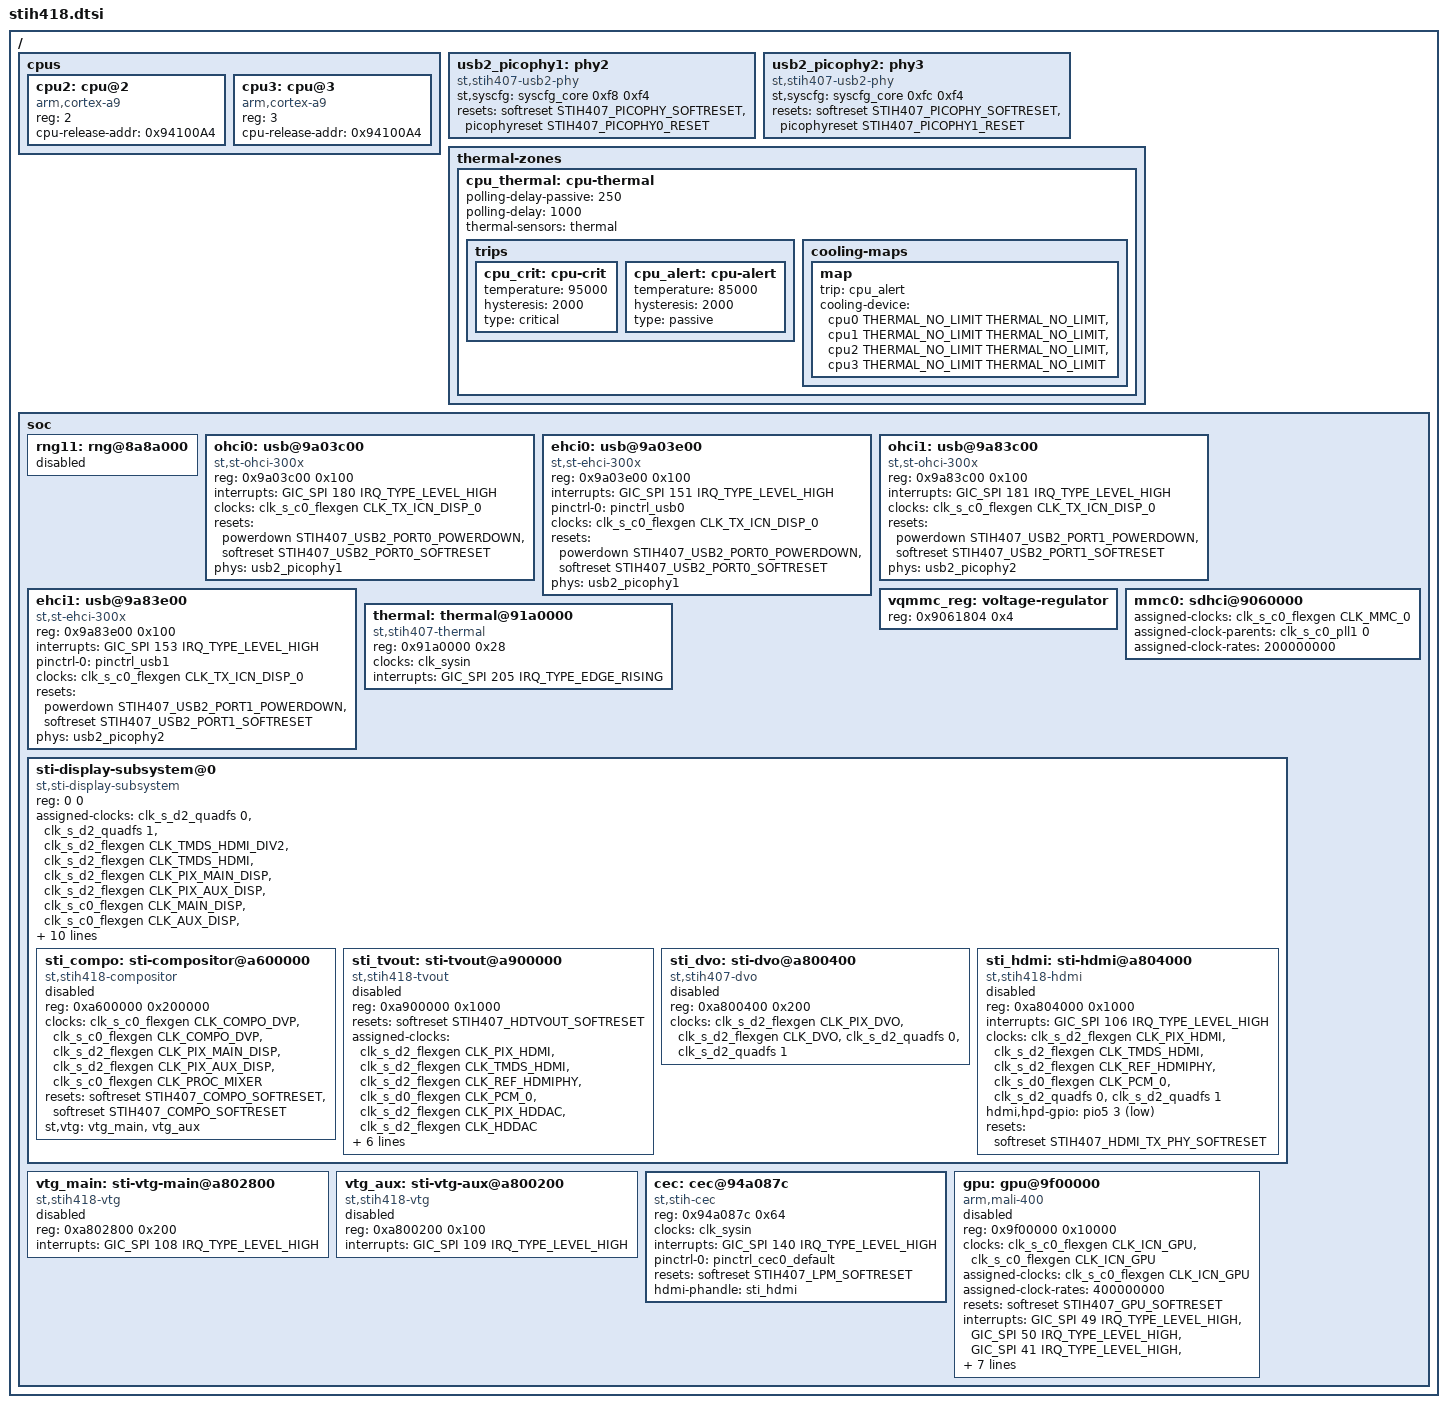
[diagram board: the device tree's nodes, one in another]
// SPDX-License-Identifier: GPL-2.0-only
/*
 * Copyright (C) 2014 STMicroelectronics Limited.
 * Author: Peter Griffin <peter.griffin@linaro.org>
 */
#include "stih418-clock.dtsi"
#include "stih407-family.dtsi"
#include "stih410-pinctrl.dtsi"
#include <dt-bindings/gpio/gpio.h>
#include <dt-bindings/thermal/thermal.h>
/ {
	cpus {
		#address-cells = <1>;
		#size-cells = <0>;
		cpu2: cpu@2 {
			device_type = "cpu";
			compatible = "arm,cortex-a9";
			reg = <2>;
			/* u-boot puts hpen in SBC dmem at 0xa4 offset */
			cpu-release-addr = <0x94100A4>;
			#cooling-cells = <2>;
		};
		cpu3: cpu@3 {
			device_type = "cpu";
			compatible = "arm,cortex-a9";
			reg = <3>;
			/* u-boot puts hpen in SBC dmem at 0xa4 offset */
			cpu-release-addr = <0x94100A4>;
			#cooling-cells = <2>;
		};
	};

	usb2_picophy1: phy2 {
		compatible = "st,stih407-usb2-phy";
		#phy-cells = <0>;
		st,syscfg = <&syscfg_core 0xf8 0xf4>;
		resets = <&softreset STIH407_PICOPHY_SOFTRESET>,
			 <&picophyreset STIH407_PICOPHY0_RESET>;
		reset-names = "global", "port";
	};

	usb2_picophy2: phy3 {
		compatible = "st,stih407-usb2-phy";
		#phy-cells = <0>;
		st,syscfg = <&syscfg_core 0xfc 0xf4>;
		resets = <&softreset STIH407_PICOPHY_SOFTRESET>,
			 <&picophyreset STIH407_PICOPHY1_RESET>;
		reset-names = "global", "port";
	};

	thermal-zones {
		cpu_thermal: cpu-thermal {
			polling-delay-passive = <250>;  /* 250ms */
			polling-delay = <1000>;         /* 1000ms */

			thermal-sensors = <&thermal>;

			trips {
				cpu_crit: cpu-crit {
					temperature = <95000>;  /* 95C */
					hysteresis = <2000>;
					type = "critical";
				};
				cpu_alert: cpu-alert {
					temperature = <85000>;  /* 85C */
					hysteresis = <2000>;
					type = "passive";
				};
			};

			cooling-maps {
				map {
					trip = <&cpu_alert>;
					cooling-device = <&cpu0 THERMAL_NO_LIMIT THERMAL_NO_LIMIT>,
							 <&cpu1 THERMAL_NO_LIMIT THERMAL_NO_LIMIT>,
							 <&cpu2 THERMAL_NO_LIMIT THERMAL_NO_LIMIT>,
							 <&cpu3 THERMAL_NO_LIMIT THERMAL_NO_LIMIT>;
				};
			};
		};
	};

	soc {
		rng11: rng@8a8a000 {
			status = "disabled";
		};

		ohci0: usb@9a03c00 {
			compatible = "st,st-ohci-300x";
			reg = <0x9a03c00 0x100>;
			interrupts = <GIC_SPI 180 IRQ_TYPE_LEVEL_HIGH>;
			clocks = <&clk_s_c0_flexgen CLK_TX_ICN_DISP_0>;
			resets = <&powerdown STIH407_USB2_PORT0_POWERDOWN>,
				 <&softreset STIH407_USB2_PORT0_SOFTRESET>;
			reset-names = "power", "softreset";
			phys = <&usb2_picophy1>;
			phy-names = "usb";
		};

		ehci0: usb@9a03e00 {
			compatible = "st,st-ehci-300x";
			reg = <0x9a03e00 0x100>;
			interrupts = <GIC_SPI 151 IRQ_TYPE_LEVEL_HIGH>;
			pinctrl-names = "default";
			pinctrl-0 = <&pinctrl_usb0>;
			clocks = <&clk_s_c0_flexgen CLK_TX_ICN_DISP_0>;
			resets = <&powerdown STIH407_USB2_PORT0_POWERDOWN>,
				 <&softreset STIH407_USB2_PORT0_SOFTRESET>;
			reset-names = "power", "softreset";
			phys = <&usb2_picophy1>;
			phy-names = "usb";
		};

		ohci1: usb@9a83c00 {
			compatible = "st,st-ohci-300x";
			reg = <0x9a83c00 0x100>;
			interrupts = <GIC_SPI 181 IRQ_TYPE_LEVEL_HIGH>;
			clocks = <&clk_s_c0_flexgen CLK_TX_ICN_DISP_0>;
			resets = <&powerdown STIH407_USB2_PORT1_POWERDOWN>,
				 <&softreset STIH407_USB2_PORT1_SOFTRESET>;
			reset-names = "power", "softreset";
			phys = <&usb2_picophy2>;
			phy-names = "usb";
		};

		ehci1: usb@9a83e00 {
			compatible = "st,st-ehci-300x";
			reg = <0x9a83e00 0x100>;
			interrupts = <GIC_SPI 153 IRQ_TYPE_LEVEL_HIGH>;
			pinctrl-names = "default";
			pinctrl-0 = <&pinctrl_usb1>;
			clocks = <&clk_s_c0_flexgen CLK_TX_ICN_DISP_0>;
			resets = <&powerdown STIH407_USB2_PORT1_POWERDOWN>,
				 <&softreset STIH407_USB2_PORT1_SOFTRESET>;
			reset-names = "power", "softreset";
			phys = <&usb2_picophy2>;
			phy-names = "usb";
		};

		vqmmc_reg: voltage-regulator {
			reg = <0x9061804 0x4>;
		};

		mmc0: sdhci@9060000 {
			assigned-clocks = <&clk_s_c0_flexgen CLK_MMC_0>;
			assigned-clock-parents = <&clk_s_c0_pll1 0>;
			assigned-clock-rates = <200000000>;
		};

		thermal: thermal@91a0000 {
			compatible = "st,stih407-thermal";
			reg = <0x91a0000 0x28>;
			clock-names = "thermal";
			clocks = <&clk_sysin>;
			interrupts = <GIC_SPI 205 IRQ_TYPE_EDGE_RISING>;
			#thermal-sensor-cells = <0>;
		};

		sti-display-subsystem@0 {
			compatible = "st,sti-display-subsystem";
			#address-cells = <1>;
			#size-cells = <1>;

			reg = <0 0>;
			assigned-clocks = <&clk_s_d2_quadfs 0>,
					  <&clk_s_d2_quadfs 1>,
					  <&clk_s_d2_flexgen CLK_TMDS_HDMI_DIV2>,
					  <&clk_s_d2_flexgen CLK_TMDS_HDMI>,
					  <&clk_s_d2_flexgen CLK_PIX_MAIN_DISP>,
					  <&clk_s_d2_flexgen CLK_PIX_AUX_DISP>,
					  <&clk_s_c0_flexgen CLK_MAIN_DISP>,
					  <&clk_s_c0_flexgen CLK_AUX_DISP>,
					  <&clk_s_c0_flexgen CLK_COMPO_DVP>,
					  <&clk_s_c0_flexgen CLK_PROC_MIXER>;

			assigned-clock-parents = <0>,
						 <0>,
						 <&clk_tmdsout_hdmi>,
						 <&clk_tmdsout_hdmi>,
						 <&clk_s_d2_quadfs 0>,
						 <&clk_s_d2_quadfs 1>,
						 <&clk_s_c0_pll1 0>,
						 <&clk_s_c0_pll1 0>,
						 <&clk_s_c0_pll0 0>,
						 <&clk_s_c0_pll0 0>;

			assigned-clock-rates = <297000000>,
					       <108000000>,
					       <297000000>,
					       <0>,
					       <74250000>,
					       <13500000>,
					       <400000000>,
					       <400000000>,
					       <355000000>,
					       <355000000>;

			ranges;

			sti_compo: sti-compositor@a600000 {
				compatible = "st,stih418-compositor";
				reg = <0xa600000 0x200000>;

				clock-names = "compo_main",
					      "compo_aux",
					      "pix_main",
					      "pix_aux",
					      "proc_mixer";

				clocks = <&clk_s_c0_flexgen CLK_COMPO_DVP>,
					 <&clk_s_c0_flexgen CLK_COMPO_DVP>,
					 <&clk_s_d2_flexgen CLK_PIX_MAIN_DISP>,
					 <&clk_s_d2_flexgen CLK_PIX_AUX_DISP>,
					 <&clk_s_c0_flexgen CLK_PROC_MIXER>;

				reset-names = "compo-main", "compo-aux";
				resets = <&softreset STIH407_COMPO_SOFTRESET>,
					 <&softreset STIH407_COMPO_SOFTRESET>;
				st,vtg = <&vtg_main>, <&vtg_aux>;

				status = "disabled";
			};

			sti_tvout: sti-tvout@a900000 {
				compatible = "st,stih418-tvout";
				reg = <0xa900000 0x1000>;
				reg-names = "tvout-reg";
				reset-names = "tvout";
				resets = <&softreset STIH407_HDTVOUT_SOFTRESET>;
				#address-cells = <1>;
				#size-cells = <1>;
				assigned-clocks = <&clk_s_d2_flexgen CLK_PIX_HDMI>,
						  <&clk_s_d2_flexgen CLK_TMDS_HDMI>,
						  <&clk_s_d2_flexgen CLK_REF_HDMIPHY>,
						  <&clk_s_d0_flexgen CLK_PCM_0>,
						  <&clk_s_d2_flexgen CLK_PIX_HDDAC>,
						  <&clk_s_d2_flexgen CLK_HDDAC>;

				assigned-clock-parents = <&clk_s_d2_quadfs 0>,
							 <&clk_tmdsout_hdmi>,
							 <&clk_s_d2_quadfs 0>,
							 <&clk_s_d0_quadfs 0>,
							 <&clk_s_d2_quadfs 0>,
							 <&clk_s_d2_quadfs 0>;
				assigned-clock-rates = <74250000>,
						       <0>,
						       <74250000>,
						       <0>,
						       <74250000>,
						       <148500000>;

				status = "disabled";
			};

			sti_dvo: sti-dvo@a800400 {
				compatible = "st,stih407-dvo";
				reg = <0xa800400 0x200>;
				reg-names = "dvo-reg";
				clock-names = "dvo_pix", "dvo",
					      "main_parent", "aux_parent";
				clocks = <&clk_s_d2_flexgen CLK_PIX_DVO>,
					 <&clk_s_d2_flexgen CLK_DVO>,
					 <&clk_s_d2_quadfs 0>, <&clk_s_d2_quadfs 1>;
				status = "disabled";
			};

			sti_hdmi: sti-hdmi@a804000 {
				compatible = "st,stih418-hdmi";
				reg = <0xa804000 0x1000>;
				reg-names = "hdmi-reg";
				#sound-dai-cells = <0>;
				interrupts = <GIC_SPI 106 IRQ_TYPE_LEVEL_HIGH>;
				interrupt-names = "irq";
				clock-names = "pix",
					      "tmds",
					      "phy",
					      "audio",
					      "main_parent",
					      "aux_parent";

				clocks = <&clk_s_d2_flexgen CLK_PIX_HDMI>,
					 <&clk_s_d2_flexgen CLK_TMDS_HDMI>,
					 <&clk_s_d2_flexgen CLK_REF_HDMIPHY>,
					 <&clk_s_d0_flexgen CLK_PCM_0>,
					 <&clk_s_d2_quadfs 0>,
					 <&clk_s_d2_quadfs 1>;

				hdmi,hpd-gpio = <&pio5 3 GPIO_ACTIVE_LOW>;
				reset-names = "hdmi";
				resets = <&softreset STIH407_HDMI_TX_PHY_SOFTRESET>;

				status = "disabled";
			};
		};

		vtg_main: sti-vtg-main@a802800 {
			compatible = "st,stih418-vtg";
			reg = <0xa802800 0x200>;
			interrupts = <GIC_SPI 108 IRQ_TYPE_LEVEL_HIGH>;

			status = "disabled";
		};

		vtg_aux: sti-vtg-aux@a800200 {
			compatible = "st,stih418-vtg";
			reg = <0xa800200 0x100>;
			interrupts = <GIC_SPI 109 IRQ_TYPE_LEVEL_HIGH>;

			status = "disabled";
		};

		cec: cec@94a087c {
			compatible = "st,stih-cec";
			reg = <0x94a087c 0x64>;
			clocks = <&clk_sysin>;
			clock-names = "cec-clk";
			interrupts = <GIC_SPI 140 IRQ_TYPE_LEVEL_HIGH>;
			interrupt-names = "cec-irq";
			pinctrl-names = "default";
			pinctrl-0 = <&pinctrl_cec0_default>;
			resets = <&softreset STIH407_LPM_SOFTRESET>;
			hdmi-phandle = <&sti_hdmi>;
		};

		gpu: gpu@9f00000 {
			compatible = "arm,mali-400";
			reg = <0x9f00000 0x10000>;
			/* LIMA driver needs 2 clocks, use the same for both */
			clocks = <&clk_s_c0_flexgen CLK_ICN_GPU>,
				 <&clk_s_c0_flexgen CLK_ICN_GPU>;
			clock-names = "bus", "core";
			assigned-clocks = <&clk_s_c0_flexgen CLK_ICN_GPU>;
			assigned-clock-rates = <400000000>;
			resets = <&softreset STIH407_GPU_SOFTRESET>;
			interrupts = <GIC_SPI 49 IRQ_TYPE_LEVEL_HIGH>,
				     <GIC_SPI 50 IRQ_TYPE_LEVEL_HIGH>,
				     <GIC_SPI 41 IRQ_TYPE_LEVEL_HIGH>,
				     <GIC_SPI 45 IRQ_TYPE_LEVEL_HIGH>,
				     <GIC_SPI 42 IRQ_TYPE_LEVEL_HIGH>,
				     <GIC_SPI 46 IRQ_TYPE_LEVEL_HIGH>,
				     <GIC_SPI 43 IRQ_TYPE_LEVEL_HIGH>,
				     <GIC_SPI 47 IRQ_TYPE_LEVEL_HIGH>,
				     <GIC_SPI 44 IRQ_TYPE_LEVEL_HIGH>,
				     <GIC_SPI 48 IRQ_TYPE_LEVEL_HIGH>;
			interrupt-names = "gp",
					  "gpmmu",
					  "pp0",
					  "ppmmu0",
					  "pp1",
					  "ppmmu1",
					  "pp2",
					  "ppmmu2",
					  "pp3",
					  "ppmmu3";

			status = "disabled";
		};
	};
};
